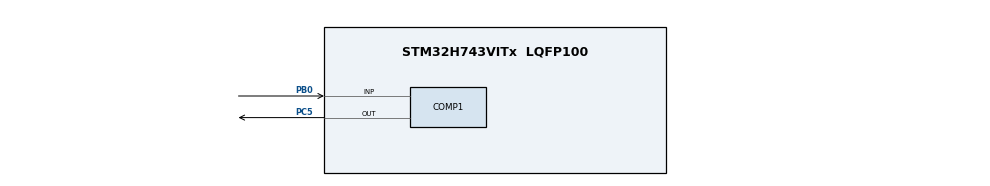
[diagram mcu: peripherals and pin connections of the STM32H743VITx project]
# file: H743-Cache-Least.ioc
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CORTEX_M7.BaseAddress_Spec=0x24000000
CORTEX_M7.CPU_DCache=Enabled
CORTEX_M7.CPU_ICache=Enabled
CORTEX_M7.DisableExec_Spec=MPU_INSTRUCTION_ACCESS_ENABLE
CORTEX_M7.IsShareable_Spec=MPU_ACCESS_NOT_SHAREABLE
CORTEX_M7.MPU_Control=MPU_HFNMI_PRIVDEF
CORTEX_M7.Size_Spec=MPU_REGION_SIZE_512B
CORTEX_M7.SubRegionDisable_Spec=0x0
CORTEX_M7.TypeExtField_Spec=MPU_TEX_LEVEL1
CORTEX_M7.default_mode_Activation=1
Mcu.Family=STM32H7
Mcu.Name=STM32H743VITx
Mcu.Package=LQFP100
NVIC.PriorityGroup=NVIC_PRIORITYGROUP_4
PA13\ (JTMS/SWDIO).Mode=Serial_Wire
PA13\ (JTMS/SWDIO).Signal=DEBUG_JTMS-SWDIO
PA14\ (JTCK/SWCLK).Mode=Serial_Wire
PA14\ (JTCK/SWCLK).Signal=DEBUG_JTCK-SWCLK
PB0.Mode=INP
PB0.Signal=COMP1_INP
PC14-OSC32_IN\ (OSC32_IN).Mode=LSE-External-Oscillator
PC14-OSC32_IN\ (OSC32_IN).Signal=RCC_OSC32_IN
PC15-OSC32_OUT\ (OSC32_OUT).Mode=LSE-External-Oscillator
PC15-OSC32_OUT\ (OSC32_OUT).Signal=RCC_OSC32_OUT
PC5.Mode=ExternalOutput
PC5.Signal=COMP1_OUT
PH0-OSC_IN\ (PH0).Mode=HSE-External-Oscillator
PH0-OSC_IN\ (PH0).Signal=RCC_OSC_IN
PH1-OSC_OUT\ (PH1).Mode=HSE-External-Oscillator
PH1-OSC_OUT\ (PH1).Signal=RCC_OSC_OUT
ProjectManager.HeapSize=0x200
ProjectManager.StackSize=0x400
ProjectManager.TargetToolchain=MDK-ARM V5.32
RCC.ADCFreq_Value=129000000
RCC.APB1Freq_Value=120000000
RCC.APB2Freq_Value=120000000
RCC.APB3Freq_Value=120000000
RCC.APB4Freq_Value=120000000
RCC.CortexFreq_Value=480000000
RCC.D1PPRE=RCC_APB3_DIV2
RCC.D2PPRE1=RCC_APB1_DIV2
RCC.D2PPRE2=RCC_APB2_DIV2
RCC.D3PPRE=RCC_APB4_DIV2
RCC.DIVM1=4
RCC.DIVN1=60
RCC.HCLKFreq_Value=240000000
RCC.HPRE=RCC_HCLK_DIV2
RCC.PLL2FRACN=0
RCC.PLL3FRACN=0
RCC.PLLFRACN=0
RCC.SYSCLKFreq_VALUE=480000000
RCC.SYSCLKSource=RCC_SYSCLKSOURCE_PLLCLK
RCC.USBFreq_Value=480000000
VP_COMP1_VS_VREFINT14.Mode=VREFINT_14
VP_MEMORYMAP_VS_MEMORYMAP.Mode=CurAppReg
board=custom

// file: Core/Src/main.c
/* USER CODE BEGIN Header */
/**
  ******************************************************************************
  * @file           : main.c
  * @brief          : Main program body
  ******************************************************************************
  * @attention
  *
  * Copyright (c) 2026 STMicroelectronics.
  * All rights reserved.
  *
  * This software is licensed under terms that can be found in the LICENSE file
  * in the root directory of this software component.
  * If no LICENSE file comes with this software, it is provided AS-IS.
  *
  ******************************************************************************
  */
/* USER CODE END Header */
#include "main.h"
#include "comp.h"
#include "gpio.h"

/* USER CODE BEGIN PV */
__attribute__((section (".AXI_SRAM"))) uint16_t adc_buffer[1024];
/* USER CODE END PV */

void SystemClock_Config(void);
static void MPU_Config(void);

int main(void)
{

  /* MPU Configuration--------------------------------------------------------*/
  MPU_Config();

  /* Enable the CPU Cache */

  /* Enable I-Cache---------------------------------------------------------*/
  SCB_EnableICache();

  /* Enable D-Cache---------------------------------------------------------*/
  SCB_EnableDCache();

  /* MCU Configuration--------------------------------------------------------*/

  /* Reset of all peripherals, Initializes the Flash interface and the Systick. */
  HAL_Init();

  /* Configure the system clock */
  SystemClock_Config();

  /* Initialize all configured peripherals */
  MX_GPIO_Init();
  MX_COMP1_Init();
  /* USER CODE BEGIN 2 */

  /* 启动比较器，使能 COMP1 */
  HAL_COMP_Start(&hcomp1);

  /* USER CODE END 2 */

  /* Infinite loop */
  while (1)
  {

    /* USER CODE BEGIN 3 */
    /* 读取比较器输出电平（0=低，1=高） */
    uint32_t comp_out = HAL_COMP_GetOutputLevel(&hcomp1);

    /* 防止编译器优化掉 comp_out，加上一个空操作引用 */
    (void)comp_out;
  }
  /* USER CODE END 3 */
}

void SystemClock_Config(void)
{
  RCC_OscInitTypeDef RCC_OscInitStruct = {0};
  RCC_ClkInitTypeDef RCC_ClkInitStruct = {0};

  /** Supply configuration update enable
  */
  HAL_PWREx_ConfigSupply(PWR_LDO_SUPPLY);

  /** Configure the main internal regulator output voltage
  */
  __HAL_PWR_VOLTAGESCALING_CONFIG(PWR_REGULATOR_VOLTAGE_SCALE0);

  while(!__HAL_PWR_GET_FLAG(PWR_FLAG_VOSRDY)) {}

  /** Initializes the RCC Oscillators according to the specified parameters
  * in the RCC_OscInitTypeDef structure.
  */
  RCC_OscInitStruct.OscillatorType = RCC_OSCILLATORTYPE_HSI;
  RCC_OscInitStruct.HSIState = RCC_HSI_DIV1;
  RCC_OscInitStruct.HSICalibrationValue = RCC_HSICALIBRATION_DEFAULT;
  RCC_OscInitStruct.PLL.PLLState = RCC_PLL_ON;
  RCC_OscInitStruct.PLL.PLLSource = RCC_PLLSOURCE_HSI;
  RCC_OscInitStruct.PLL.PLLM = 4;
  RCC_OscInitStruct.PLL.PLLN = 60;
  RCC_OscInitStruct.PLL.PLLP = 2;
  RCC_OscInitStruct.PLL.PLLQ = 2;
  RCC_OscInitStruct.PLL.PLLR = 2;
  RCC_OscInitStruct.PLL.PLLRGE = RCC_PLL1VCIRANGE_3;
  RCC_OscInitStruct.PLL.PLLVCOSEL = RCC_PLL1VCOWIDE;
  RCC_OscInitStruct.PLL.PLLFRACN = 0;
  if (HAL_RCC_OscConfig(&RCC_OscInitStruct) != HAL_OK)
  {
    Error_Handler();
  }

  /** Initializes the CPU, AHB and APB buses clocks
  */
  RCC_ClkInitStruct.ClockType = RCC_CLOCKTYPE_HCLK|RCC_CLOCKTYPE_SYSCLK
                              |RCC_CLOCKTYPE_PCLK1|RCC_CLOCKTYPE_PCLK2
                              |RCC_CLOCKTYPE_D3PCLK1|RCC_CLOCKTYPE_D1PCLK1;
  RCC_ClkInitStruct.SYSCLKSource = RCC_SYSCLKSOURCE_PLLCLK;
  RCC_ClkInitStruct.SYSCLKDivider = RCC_SYSCLK_DIV1;
  RCC_ClkInitStruct.AHBCLKDivider = RCC_HCLK_DIV2;
  RCC_ClkInitStruct.APB3CLKDivider = RCC_APB3_DIV2;
  RCC_ClkInitStruct.APB1CLKDivider = RCC_APB1_DIV2;
  RCC_ClkInitStruct.APB2CLKDivider = RCC_APB2_DIV2;
  RCC_ClkInitStruct.APB4CLKDivider = RCC_APB4_DIV2;

  if (HAL_RCC_ClockConfig(&RCC_ClkInitStruct, FLASH_LATENCY_4) != HAL_OK)
  {
    Error_Handler();
  }
}

 /* MPU Configuration */

void MPU_Config(void)
{
  MPU_Region_InitTypeDef MPU_InitStruct = {0};

  /* Disables the MPU */
  HAL_MPU_Disable();

  /** Initializes and configures the Region and the memory to be protected
  */
  MPU_InitStruct.Enable = MPU_REGION_ENABLE;
  MPU_InitStruct.Number = MPU_REGION_NUMBER0;
  MPU_InitStruct.BaseAddress = 0x24000000;
  MPU_InitStruct.Size = MPU_REGION_SIZE_512B;
  MPU_InitStruct.SubRegionDisable = 0x0;
  MPU_InitStruct.TypeExtField = MPU_TEX_LEVEL1;
  MPU_InitStruct.AccessPermission = MPU_REGION_NO_ACCESS;
  MPU_InitStruct.DisableExec = MPU_INSTRUCTION_ACCESS_ENABLE;
  MPU_InitStruct.IsShareable = MPU_ACCESS_NOT_SHAREABLE;
  MPU_InitStruct.IsCacheable = MPU_ACCESS_NOT_CACHEABLE;
  MPU_InitStruct.IsBufferable = MPU_ACCESS_NOT_BUFFERABLE;

  HAL_MPU_ConfigRegion(&MPU_InitStruct);
  /* Enables the MPU */
  HAL_MPU_Enable(MPU_HFNMI_PRIVDEF);

}

void Error_Handler(void)
{
  __disable_irq();
  while (1)
  {
  }
}
